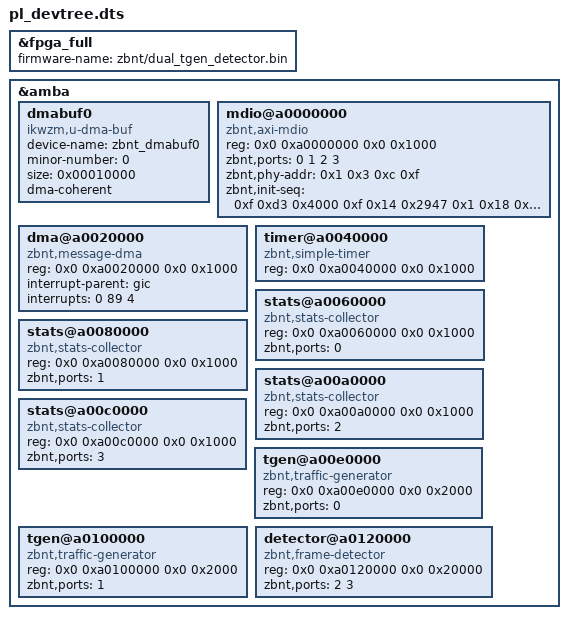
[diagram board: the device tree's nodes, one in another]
/*
	This Source Code Form is subject to the terms of the Mozilla Public
	License, v. 2.0. If a copy of the MPL was not distributed with this
	file, You can obtain one at https://mozilla.org/MPL/2.0/.
*/

/dts-v1/;
/plugin/;

/ {
	fragment@0 {
		target = <&fpga_full>;

		__overlay__ {
			firmware-name = "zbnt/dual_tgen_detector.bin";
		};
	};

	fragment@1 {
		target = <&amba>;

		__overlay__ {
			#address-cells = <1>;
			#size-cells = <1>;

			dmabuf0 {
				compatible = "ikwzm,u-dma-buf";
				device-name = "zbnt_dmabuf0";
				minor-number = <0>;
				size = <0x00010000>;
				dma-coherent;
			};

			mdio@a0000000 {
				compatible = "zbnt,axi-mdio", "generic-uio";
				reg = <0x0 0xa0000000 0x0 0x1000>;

				zbnt,ports = <0 1 2 3>;
				zbnt,phy-addr = <0x1 0x3 0xc 0xf>;

				zbnt,init-seq = <
					/* Enable 625MHz clock */
					0xf 0xd3 0x4000

					/* Disable SGMII auto-negotiation */
					0xf 0x14 0x2947

					/* Set LED modes */
					0x1 0x18 0x615b
					0x3 0x18 0x615b
					0xc 0x18 0x615b
					0xf 0x18 0x615b
				>;
			};

			dma@a0020000 {
				compatible = "zbnt,message-dma", "generic-uio";
				reg = <0x0 0xa0020000 0x0 0x1000>;

				interrupt-names = "irq0";
				interrupt-parent = <&gic>;
				interrupts = <0 89 4>;
			};

			timer@a0040000 {
				compatible = "zbnt,simple-timer", "generic-uio";
				reg = <0x0 0xa0040000 0x0 0x1000>;
			};

			stats@a0060000 {
				compatible = "zbnt,stats-collector", "generic-uio";
				reg = <0x0 0xa0060000 0x0 0x1000>;

				zbnt,ports = <0>;
			};

			stats@a0080000 {
				compatible = "zbnt,stats-collector", "generic-uio";
				reg = <0x0 0xa0080000 0x0 0x1000>;

				zbnt,ports = <1>;
			};

			stats@a00a0000 {
				compatible = "zbnt,stats-collector", "generic-uio";
				reg = <0x0 0xa00a0000 0x0 0x1000>;

				zbnt,ports = <2>;
			};

			stats@a00c0000 {
				compatible = "zbnt,stats-collector", "generic-uio";
				reg = <0x0 0xa00c0000 0x0 0x1000>;

				zbnt,ports = <3>;
			};

			tgen@a00e0000 {
				compatible = "zbnt,traffic-generator", "generic-uio";
				reg = <0x0 0xa00e0000 0x0 0x2000>;

				zbnt,ports = <0>;
			};

			tgen@a0100000 {
				compatible = "zbnt,traffic-generator", "generic-uio";
				reg = <0x0 0xa0100000 0x0 0x2000>;

				zbnt,ports = <1>;
			};

			detector@a0120000 {
				compatible = "zbnt,frame-detector", "generic-uio";
				reg = <0x0 0xa0120000 0x0 0x20000>;

				zbnt,ports = <2 3>;
			};
		};
	};
};
